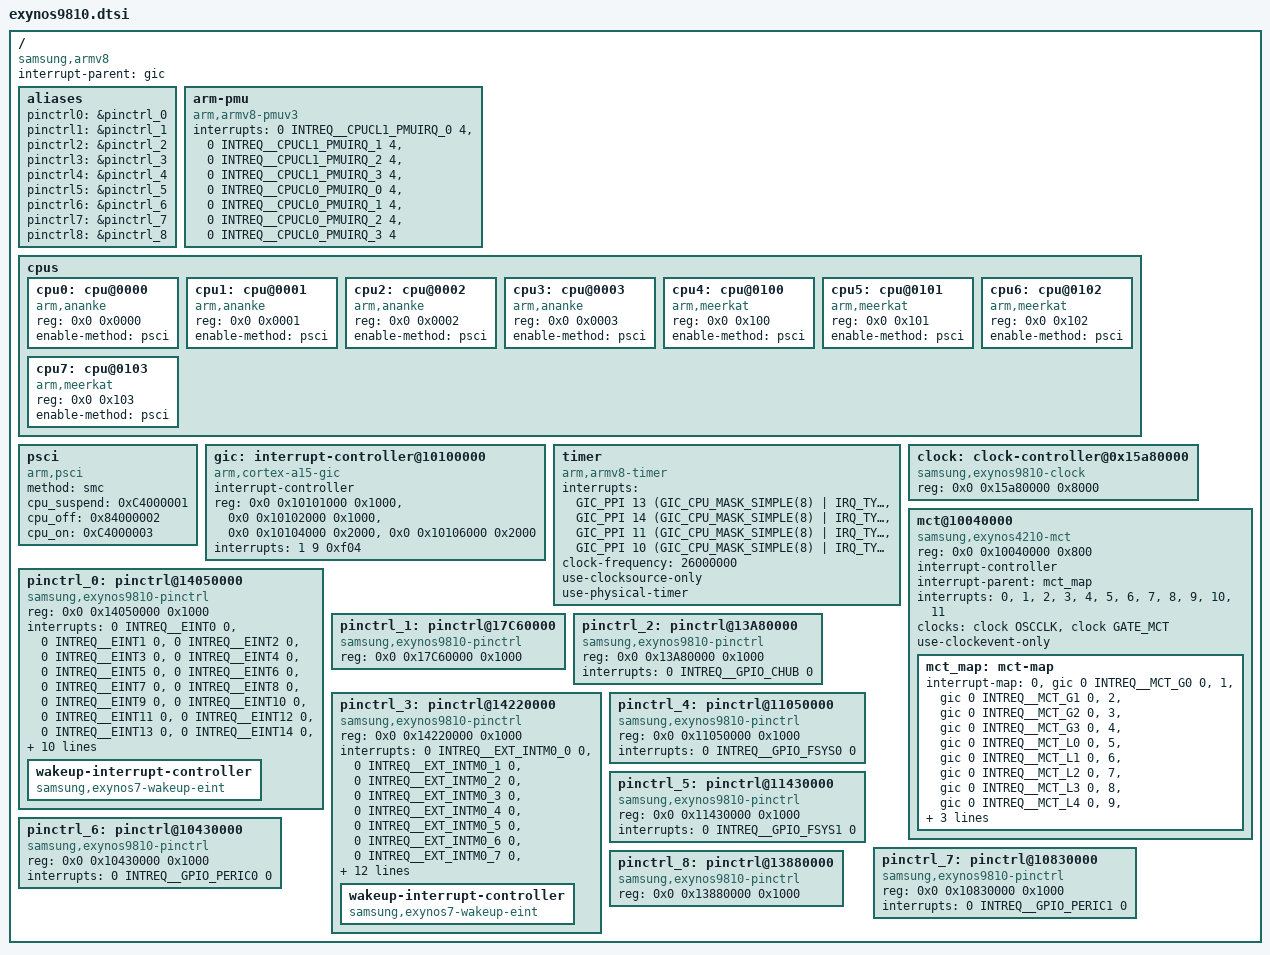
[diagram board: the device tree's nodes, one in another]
/*
 * SAMSUNG EXYNOS9810 SoC device tree source
 *
 * Copyright (c) 2017 Samsung Electronics Co., Ltd.
 *		http://www.samsung.com
 *
 * SAMSUNG EXYNOS9810 SoC device nodes are listed in this file.
 * EXYNOS9810 based board files can include this file and provide
 * values for board specfic bindings.
 *
 * This program is free software; you can redistribute it and/or modify
 * it under the terms of the GNU General Public License version 2 as
 * published by the Free Software Foundation.
 */

#include <dt-bindings/clock/exynos9810.h>
#include <dt-bindings/interrupt-controller/exynos9810.h>
#include "exynos9810-pinctrl.dtsi"

/ {
	compatible = "samsung,armv8", "samsung,exynos9810";
	interrupt-parent = <&gic>;
	#address-cells = <2>;
	#size-cells = <1>;

	aliases {
		pinctrl0 = &pinctrl_0;
		pinctrl1 = &pinctrl_1;
		pinctrl2 = &pinctrl_2;
		pinctrl3 = &pinctrl_3;
		pinctrl4 = &pinctrl_4;
		pinctrl5 = &pinctrl_5;
		pinctrl6 = &pinctrl_6;
		pinctrl7 = &pinctrl_7;
		pinctrl8 = &pinctrl_8;
	};

	arm-pmu {
		compatible = "arm,armv8-pmuv3";
		interrupts = <0 INTREQ__CPUCL1_PMUIRQ_0 4>,
			     <0 INTREQ__CPUCL1_PMUIRQ_1 4>,
			     <0 INTREQ__CPUCL1_PMUIRQ_2 4>,
			     <0 INTREQ__CPUCL1_PMUIRQ_3 4>,
			     <0 INTREQ__CPUCL0_PMUIRQ_0 4>,
			     <0 INTREQ__CPUCL0_PMUIRQ_1 4>,
			     <0 INTREQ__CPUCL0_PMUIRQ_2 4>,
			     <0 INTREQ__CPUCL0_PMUIRQ_3 4>;
	};

	cpus {
		#address-cells = <2>;
		#size-cells = <0>;

		cpu0: cpu@0000 {
			device_type = "cpu";
			compatible = "arm,ananke", "arm,armv8";
			reg = <0x0 0x0000>;
			enable-method = "psci";
		};
		cpu1: cpu@0001 {
			device_type = "cpu";
			compatible = "arm,ananke", "arm,armv8";
			reg = <0x0 0x0001>;
			enable-method = "psci";
		};
		cpu2: cpu@0002 {
			device_type = "cpu";
			compatible = "arm,ananke", "arm,armv8";
			reg = <0x0 0x0002>;
			enable-method = "psci";
		};
		cpu3: cpu@0003 {
			device_type = "cpu";
			compatible = "arm,ananke", "arm,armv8";
			reg = <0x0 0x0003>;
			enable-method = "psci";
		};
		cpu4: cpu@0100 {
			device_type = "cpu";
			compatible = "arm,meerkat", "arm,armv8";
			reg = <0x0 0x100>;
			enable-method = "psci";
		};
		cpu5: cpu@0101 {
			device_type = "cpu";
			compatible = "arm,meerkat", "arm,armv8";
			reg = <0x0 0x101>;
			enable-method = "psci";
		};
		cpu6: cpu@0102 {
			device_type = "cpu";
			compatible = "arm,meerkat", "arm,armv8";
			reg = <0x0 0x102>;
			enable-method = "psci";
		};
		cpu7: cpu@0103 {
			device_type = "cpu";
			compatible = "arm,meerkat", "arm,armv8";
			reg = <0x0 0x103>;
			enable-method = "psci";
		};
	};

	psci {
		compatible = "arm,psci";
		method = "smc";
		cpu_suspend = <0xC4000001>;
		cpu_off = <0x84000002>;
		cpu_on = <0xC4000003>;
	};

	gic:interrupt-controller@10100000 {
		compatible = "arm,cortex-a15-gic", "arm,cortex-a9-gic";
		#interrupt-cells = <3>;
		#address-cells = <0>;
		interrupt-controller;
		reg =	<0x0 0x10101000 0x1000>,
			<0x0 0x10102000 0x1000>,
			<0x0 0x10104000 0x2000>,
			<0x0 0x10106000 0x2000>;
		interrupts = <1 9 0xf04>;
	};

	timer {
		compatible = "arm,armv8-timer";
		interrupts = <GIC_PPI 13
				(GIC_CPU_MASK_SIMPLE(8) | IRQ_TYPE_LEVEL_LOW)>,
			     <GIC_PPI 14
				(GIC_CPU_MASK_SIMPLE(8) | IRQ_TYPE_LEVEL_LOW)>,
			     <GIC_PPI 11
				(GIC_CPU_MASK_SIMPLE(8) | IRQ_TYPE_LEVEL_LOW)>,
			     <GIC_PPI 10
				(GIC_CPU_MASK_SIMPLE(8) | IRQ_TYPE_LEVEL_LOW)>;
		clock-frequency = <26000000>;
		use-clocksource-only;
		use-physical-timer;
	};

	clock: clock-controller@0x15a80000 {
		compatible = "samsung,exynos9810-clock";
		reg = <0x0 0x15a80000 0x8000>;
		#clock-cells = <1>;
	};

	mct@10040000 {
		compatible = "samsung,exynos4210-mct";
		reg = <0x0 0x10040000 0x800>;
		interrupt-controller;
		#interrupt-cells = <1>;
		interrupt-parent = <&mct_map>;
		interrupts =	<0>, <1>, <2>, <3>,
				<4>, <5>, <6>, <7>,
				<8>, <9>, <10>, <11>;
		clocks = <&clock OSCCLK>, <&clock GATE_MCT>;
		clock-names = "fin_pll", "mct";
		use-clockevent-only;

		mct_map: mct-map {
			#interrupt-cells = <1>;
			#address-cells = <0>;
			#size-cells = <0>;
			interrupt-map = <0 &gic 0 INTREQ__MCT_G0 0>,
					<1 &gic 0 INTREQ__MCT_G1 0>,
					<2 &gic 0 INTREQ__MCT_G2 0>,
					<3 &gic 0 INTREQ__MCT_G3 0>,
					<4 &gic 0 INTREQ__MCT_L0 0>,
					<5 &gic 0 INTREQ__MCT_L1 0>,
					<6 &gic 0 INTREQ__MCT_L2 0>,
					<7 &gic 0 INTREQ__MCT_L3 0>,
					<8 &gic 0 INTREQ__MCT_L4 0>,
					<9 &gic 0 INTREQ__MCT_L5 0>,
					<10 &gic 0 INTREQ__MCT_L6 0>,
					<11 &gic 0 INTREQ__MCT_L7 0>;
		};
	};

	/* ALIVE */
	pinctrl_0: pinctrl@14050000 {
		compatible = "samsung,exynos9810-pinctrl";
		reg = <0x0 0x14050000 0x1000>;
		interrupts = <0 INTREQ__EINT0 0>, <0 INTREQ__EINT1 0>, <0 INTREQ__EINT2 0>,
			     <0 INTREQ__EINT3 0>, <0 INTREQ__EINT4 0>, <0 INTREQ__EINT5 0>,
			     <0 INTREQ__EINT6 0>, <0 INTREQ__EINT7 0>, <0 INTREQ__EINT8 0>,
			     <0 INTREQ__EINT9 0>, <0 INTREQ__EINT10 0>, <0 INTREQ__EINT11 0>,
			     <0 INTREQ__EINT12 0>, <0 INTREQ__EINT13 0>, <0 INTREQ__EINT14 0>,
			     <0 INTREQ__EINT15 0>, <0 INTREQ__EINT16 0>, <0 INTREQ__EINT17 0>,
			     <0 INTREQ__EINT18 0>, <0 INTREQ__EINT19 0>, <0 INTREQ__EINT20 0>,
			     <0 INTREQ__EINT21 0>, <0 INTREQ__EINT22 0>, <0 INTREQ__EINT23 0>,
			     <0 INTREQ__EINT24 0>, <0 INTREQ__EINT25 0>, <0 INTREQ__EINT26 0>,
			     <0 INTREQ__EINT27 0>, <0 INTREQ__EINT28 0>, <0 INTREQ__EINT29 0>,
			     <0 INTREQ__EINT30 0>, <0 INTREQ__EINT31 0>, <0 INTREQ__EINT32 0>,
			     <0 INTREQ__EINT33 0>;

		wakeup-interrupt-controller {
			compatible = "samsung,exynos7-wakeup-eint";
		};
	};

	/* AUD */
	pinctrl_1: pinctrl@17C60000{
		compatible = "samsung,exynos9810-pinctrl";
		reg = <0x0 0x17C60000 0x1000>;
	};

	/* CHUB */
	pinctrl_2: pinctrl@13A80000{
		compatible = "samsung,exynos9810-pinctrl";
		reg = <0x0 0x13A80000 0x1000>;
		interrupts = <0 INTREQ__GPIO_CHUB 0>;
	};

	/* CMGP */
	pinctrl_3: pinctrl@14220000{
		compatible = "samsung,exynos9810-pinctrl";
		reg = <0x0 0x14220000 0x1000>;
		interrupts = <0 INTREQ__EXT_INTM0_0 0>, <0 INTREQ__EXT_INTM0_1 0>,
			     <0 INTREQ__EXT_INTM0_2 0>, <0 INTREQ__EXT_INTM0_3 0>,
			     <0 INTREQ__EXT_INTM0_4 0>, <0 INTREQ__EXT_INTM0_5 0>,
			     <0 INTREQ__EXT_INTM0_6 0>, <0 INTREQ__EXT_INTM0_7 0>,
			     <0 INTREQ__EXT_INTM1_0 0>, <0 INTREQ__EXT_INTM1_1 0>,
			     <0 INTREQ__EXT_INTM1_2 0>, <0 INTREQ__EXT_INTM1_3 0>,
			     <0 INTREQ__EXT_INTM1_4 0>, <0 INTREQ__EXT_INTM1_5 0>,
			     <0 INTREQ__EXT_INTM1_6 0>, <0 INTREQ__EXT_INTM1_7 0>,
			     <0 INTREQ__EXT_INTM4_0 0>, <0 INTREQ__EXT_INTM4_1 0>,
			     <0 INTREQ__EXT_INTM4_2 0>, <0 INTREQ__EXT_INTM4_3 0>;

		wakeup-interrupt-controller {
			compatible = "samsung,exynos7-wakeup-eint";
		};
	};

	/* FSYS0 */
	pinctrl_4: pinctrl@11050000 {
		compatible = "samsung,exynos9810-pinctrl";
		reg = <0x0 0x11050000 0x1000>;
		interrupts = <0 INTREQ__GPIO_FSYS0 0>;
	};

	/* FSYS1 */
	pinctrl_5: pinctrl@11430000 {
		compatible = "samsung,exynos9810-pinctrl";
		reg = <0x0 0x11430000 0x1000>;
		interrupts = <0 INTREQ__GPIO_FSYS1 0>;
	};

	/* PERIC0 */
	pinctrl_6: pinctrl@10430000 {
		compatible = "samsung,exynos9810-pinctrl";
		reg = <0x0 0x10430000 0x1000>;
		interrupts = <0 INTREQ__GPIO_PERIC0 0>;
	};

	/* PERIC1 */
	pinctrl_7: pinctrl@10830000 {
		compatible = "samsung,exynos9810-pinctrl";
		reg = <0x0 0x10830000 0x1000>;
		interrupts = <0 INTREQ__GPIO_PERIC1 0>;
	};

	/* VTS */
	pinctrl_8: pinctrl@13880000 {
		compatible = "samsung,exynos9810-pinctrl";
		reg = <0x0 0x13880000 0x1000>;
	};
};
